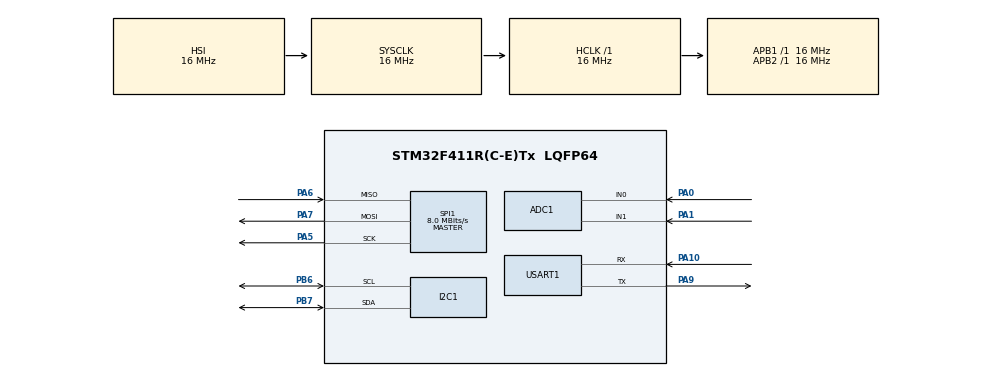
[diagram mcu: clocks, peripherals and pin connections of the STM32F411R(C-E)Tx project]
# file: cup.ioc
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ADC1.Channel-0\#ChannelRegularConversion=ADC_CHANNEL_0
ADC1.NbrOfConversionFlag=1
ADC1.Rank-0\#ChannelRegularConversion=1
ADC1.SamplingTime-0\#ChannelRegularConversion=ADC_SAMPLETIME_3CYCLES
ADC1.master=1
Mcu.Family=STM32F4
Mcu.Name=STM32F411R(C-E)Tx
Mcu.Package=LQFP64
NVIC.PriorityGroup=NVIC_PRIORITYGROUP_4
PA0-WKUP.Signal=ADCx_IN0
PA1.Signal=ADCx_IN1
PA10.Mode=Asynchronous
PA10.Signal=USART1_RX
PA5.Mode=Full_Duplex_Master
PA5.Signal=SPI1_SCK
PA6.Mode=Full_Duplex_Master
PA6.Signal=SPI1_MISO
PA7.Mode=Full_Duplex_Master
PA7.Signal=SPI1_MOSI
PA9.Mode=Asynchronous
PA9.Signal=USART1_TX
PB6.Mode=I2C
PB6.Signal=I2C1_SCL
PB7.Mode=I2C
PB7.Signal=I2C1_SDA
ProjectManager.HeapSize=0x200
ProjectManager.StackSize=0x400
ProjectManager.TargetToolchain=MDK-ARM V5
RCC.AHBFreq_Value=16000000
RCC.APB1Freq_Value=16000000
RCC.APB2Freq_Value=16000000
RCC.CortexFreq_Value=16000000
RCC.HSE_VALUE=25000000
RCC.HSI_VALUE=16000000
RCC.LSE_VALUE=32768
RCC.SYSCLKFreq_VALUE=16000000
RCC.VCOOutputFreq_Value=192000000
SH.ADCx_IN0.0=ADC1_IN0,IN0
SH.ADCx_IN1.0=ADC1_IN1,IN1
SPI1.CalculateBaudRate=8.0 MBits/s
SPI1.Mode=SPI_MODE_MASTER
board=cup

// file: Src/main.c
/**
  ******************************************************************************
  * File Name          : main.c
  * Description        : Main program body
  ******************************************************************************
  *
  * COPYRIGHT(c) 2017 STMicroelectronics
  *
  * Redistribution and use in source and binary forms, with or without modification,
  * are permitted provided that the following conditions are met:
  *   1. Redistributions of source code must retain the above copyright notice,
  *      this list of conditions and the following disclaimer.
  *   2. Redistributions in binary form must reproduce the above copyright notice,
  *      this list of conditions and the following disclaimer in the documentation
  *      and/or other materials provided with the distribution.
  *   3. Neither the name of STMicroelectronics nor the names of its contributors
  *      may be used to endorse or promote products derived from this software
  *      without specific prior written permission.
  *
  * THIS SOFTWARE IS PROVIDED BY THE COPYRIGHT HOLDERS AND CONTRIBUTORS "AS IS"
  * AND ANY EXPRESS OR IMPLIED WARRANTIES, INCLUDING, BUT NOT LIMITED TO, THE
  * IMPLIED WARRANTIES OF MERCHANTABILITY AND FITNESS FOR A PARTICULAR PURPOSE ARE
  * DISCLAIMED. IN NO EVENT SHALL THE COPYRIGHT HOLDER OR CONTRIBUTORS BE LIABLE
  * FOR ANY DIRECT, INDIRECT, INCIDENTAL, SPECIAL, EXEMPLARY, OR CONSEQUENTIAL
  * DAMAGES (INCLUDING, BUT NOT LIMITED TO, PROCUREMENT OF SUBSTITUTE GOODS OR
  * SERVICES; LOSS OF USE, DATA, OR PROFITS; OR BUSINESS INTERRUPTION) HOWEVER
  * CAUSED AND ON ANY THEORY OF LIABILITY, WHETHER IN CONTRACT, STRICT LIABILITY,
  * OR TORT (INCLUDING NEGLIGENCE OR OTHERWISE) ARISING IN ANY WAY OUT OF THE USE
  * OF THIS SOFTWARE, EVEN IF ADVISED OF THE POSSIBILITY OF SUCH DAMAGE.
  *
  ******************************************************************************
  */
#include "main.h"
#include "stm32f4xx_hal.h"

ADC_HandleTypeDef hadc1;

I2C_HandleTypeDef hi2c1;

SPI_HandleTypeDef hspi1;

UART_HandleTypeDef huart1;

/* USER CODE BEGIN PV */
/* Private variables ---------------------------------------------------------*/

/* USER CODE END PV */

void SystemClock_Config(void);
void Error_Handler(void);
static void MX_GPIO_Init(void);
static void MX_ADC1_Init(void);
static void MX_I2C1_Init(void);
static void MX_SPI1_Init(void);
static void MX_USART1_UART_Init(void);

/* USER CODE BEGIN PFP */
/* Private function prototypes -----------------------------------------------*/

/* USER CODE END PFP */

int main(void)
{

  /* MCU Configuration----------------------------------------------------------*/

  /* Reset of all peripherals, Initializes the Flash interface and the Systick. */
  HAL_Init();

  /* Configure the system clock */
  SystemClock_Config();

  /* Initialize all configured peripherals */
  MX_GPIO_Init();
  MX_ADC1_Init();
  MX_I2C1_Init();
  MX_SPI1_Init();
  MX_USART1_UART_Init();

  /* Infinite loop */
  /* USER CODE BEGIN WHILE */
	//uint32_t i = 0;
	uint8_t  string[10] = "sprindy";
	uint32_t volt_temp = 0;
	HAL_ADC_Start(&hadc1);

  while (1)
  {
  /* USER CODE END WHILE */

  /* USER CODE BEGIN 3 */

		HAL_Delay(1000);
		volt_temp = HAL_ADC_GetValue(&hadc1);
		printf("get temp adc result:%d\n", volt_temp);
  }
  /* USER CODE END 3 */

}

/** System Clock Configuration
*/
void SystemClock_Config(void)
{

  RCC_OscInitTypeDef RCC_OscInitStruct;
  RCC_ClkInitTypeDef RCC_ClkInitStruct;

    /**Configure the main internal regulator output voltage
    */
  __HAL_RCC_PWR_CLK_ENABLE();

  __HAL_PWR_VOLTAGESCALING_CONFIG(PWR_REGULATOR_VOLTAGE_SCALE1);

    /**Initializes the CPU, AHB and APB busses clocks
    */
  RCC_OscInitStruct.OscillatorType = RCC_OSCILLATORTYPE_HSI;
  RCC_OscInitStruct.HSIState = RCC_HSI_ON;
  RCC_OscInitStruct.HSICalibrationValue = 16;
  RCC_OscInitStruct.PLL.PLLState = RCC_PLL_NONE;
  if (HAL_RCC_OscConfig(&RCC_OscInitStruct) != HAL_OK)
  {
    Error_Handler();
  }

    /**Initializes the CPU, AHB and APB busses clocks
    */
  RCC_ClkInitStruct.ClockType = RCC_CLOCKTYPE_HCLK|RCC_CLOCKTYPE_SYSCLK
                              |RCC_CLOCKTYPE_PCLK1|RCC_CLOCKTYPE_PCLK2;
  RCC_ClkInitStruct.SYSCLKSource = RCC_SYSCLKSOURCE_HSI;
  RCC_ClkInitStruct.AHBCLKDivider = RCC_SYSCLK_DIV1;
  RCC_ClkInitStruct.APB1CLKDivider = RCC_HCLK_DIV1;
  RCC_ClkInitStruct.APB2CLKDivider = RCC_HCLK_DIV1;

  if (HAL_RCC_ClockConfig(&RCC_ClkInitStruct, FLASH_LATENCY_0) != HAL_OK)
  {
    Error_Handler();
  }

    /**Configure the Systick interrupt time
    */
  HAL_SYSTICK_Config(HAL_RCC_GetHCLKFreq()/1000);

    /**Configure the Systick
    */
  HAL_SYSTICK_CLKSourceConfig(SYSTICK_CLKSOURCE_HCLK);

  /* SysTick_IRQn interrupt configuration */
  HAL_NVIC_SetPriority(SysTick_IRQn, 0, 0);
}

/* ADC1 init function */
static void MX_ADC1_Init(void)
{

  ADC_ChannelConfTypeDef sConfig;

    /**Configure the global features of the ADC (Clock, Resolution, Data Alignment and number of conversion)
    */
  hadc1.Instance = ADC1;
  hadc1.Init.ClockPrescaler = ADC_CLOCK_SYNC_PCLK_DIV2;
  hadc1.Init.Resolution = ADC_RESOLUTION_12B;
  hadc1.Init.ScanConvMode = DISABLE;
  hadc1.Init.ContinuousConvMode = DISABLE;
  hadc1.Init.DiscontinuousConvMode = DISABLE;
  hadc1.Init.ExternalTrigConvEdge = ADC_EXTERNALTRIGCONVEDGE_NONE;
  hadc1.Init.DataAlign = ADC_DATAALIGN_RIGHT;
  hadc1.Init.NbrOfConversion = 1;
  hadc1.Init.DMAContinuousRequests = DISABLE;
  hadc1.Init.EOCSelection = ADC_EOC_SINGLE_CONV;
  if (HAL_ADC_Init(&hadc1) != HAL_OK)
  {
    Error_Handler();
  }

    /**Configure for the selected ADC regular channel its corresponding rank in the sequencer and its sample time.
    */
  sConfig.Channel = ADC_CHANNEL_0;
  sConfig.Rank = 1;
  sConfig.SamplingTime = ADC_SAMPLETIME_3CYCLES;
  if (HAL_ADC_ConfigChannel(&hadc1, &sConfig) != HAL_OK)
  {
    Error_Handler();
  }

}

/* I2C1 init function */
static void MX_I2C1_Init(void)
{

  hi2c1.Instance = I2C1;
  hi2c1.Init.ClockSpeed = 100000;
  hi2c1.Init.DutyCycle = I2C_DUTYCYCLE_2;
  hi2c1.Init.OwnAddress1 = 0;
  hi2c1.Init.AddressingMode = I2C_ADDRESSINGMODE_7BIT;
  hi2c1.Init.DualAddressMode = I2C_DUALADDRESS_DISABLE;
  hi2c1.Init.OwnAddress2 = 0;
  hi2c1.Init.GeneralCallMode = I2C_GENERALCALL_DISABLE;
  hi2c1.Init.NoStretchMode = I2C_NOSTRETCH_DISABLE;
  if (HAL_I2C_Init(&hi2c1) != HAL_OK)
  {
    Error_Handler();
  }

}

/* SPI1 init function */
static void MX_SPI1_Init(void)
{

  hspi1.Instance = SPI1;
  hspi1.Init.Mode = SPI_MODE_MASTER;
  hspi1.Init.Direction = SPI_DIRECTION_2LINES;
  hspi1.Init.DataSize = SPI_DATASIZE_8BIT;
  hspi1.Init.CLKPolarity = SPI_POLARITY_LOW;
  hspi1.Init.CLKPhase = SPI_PHASE_1EDGE;
  hspi1.Init.NSS = SPI_NSS_SOFT;
  hspi1.Init.BaudRatePrescaler = SPI_BAUDRATEPRESCALER_2;
  hspi1.Init.FirstBit = SPI_FIRSTBIT_MSB;
  hspi1.Init.TIMode = SPI_TIMODE_DISABLE;
  hspi1.Init.CRCCalculation = SPI_CRCCALCULATION_DISABLE;
  hspi1.Init.CRCPolynomial = 10;
  if (HAL_SPI_Init(&hspi1) != HAL_OK)
  {
    Error_Handler();
  }

}

/* USART1 init function */
static void MX_USART1_UART_Init(void)
{

  huart1.Instance = USART1;
  huart1.Init.BaudRate = 115200;
  huart1.Init.WordLength = UART_WORDLENGTH_8B;
  huart1.Init.StopBits = UART_STOPBITS_1;
  huart1.Init.Parity = UART_PARITY_NONE;
  huart1.Init.Mode = UART_MODE_TX_RX;
  huart1.Init.HwFlowCtl = UART_HWCONTROL_NONE;
  huart1.Init.OverSampling = UART_OVERSAMPLING_16;
  if (HAL_UART_Init(&huart1) != HAL_OK)
  {
    Error_Handler();
  }

}

/** Pinout Configuration
*/
static void MX_GPIO_Init(void)
{

  /* GPIO Ports Clock Enable */
  __HAL_RCC_GPIOA_CLK_ENABLE();
  __HAL_RCC_GPIOB_CLK_ENABLE();

}

void Error_Handler(void)
{
  while(1)
  {
  }
}

/************************ (C) COPYRIGHT STMicroelectronics *****END OF FILE****/
